VERSION ""

NS_ :

BS_:

BU_: XXX

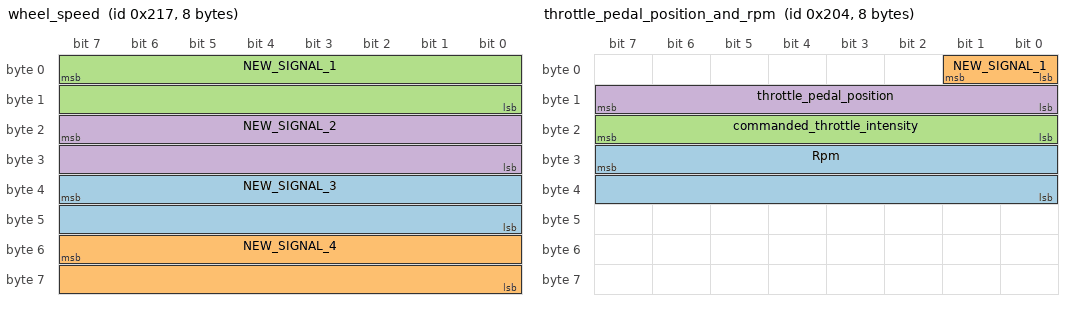
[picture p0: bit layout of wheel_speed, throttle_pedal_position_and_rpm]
BO_ 535 wheel_speed: 8 XXX
 SG_ NEW_SIGNAL_3 : 39|16@0+ (1,0) [0|65535] "" XXX
 SG_ NEW_SIGNAL_4 : 55|16@0+ (1,0) [0|65535] "" XXX
 SG_ NEW_SIGNAL_1 : 7|16@0+ (1,0) [0|65535] "" XXX
 SG_ NEW_SIGNAL_2 : 23|16@0+ (1,0) [0|65535] "" XXX

BO_ 133 steering_angle_2: 8 XXX
 SG_ NEW_SIGNAL_2 : 39|16@0+ (1,0) [0|65535] "" XXX
 SG_ NEW_SIGNAL_1 : 7|16@0+ (1,0) [0|65535] "" XXX

BO_ 516 throttle_pedal_position_and_rpm: 8 XXX
 SG_ Rpm : 31|16@0+ (2.1,0) [0|65535] "rpm" XXX
 SG_ NEW_SIGNAL_1 : 0|2@1+ (1,0) [0|3] "" XXX
 SG_ commanded_throttle_intensity : 23|8@0+ (1,0) [0|255] "" XXX
 SG_ throttle_pedal_position : 15|8@0+ (0,0) [0|255] "" XXX

BO_ 146 steering_related: 8 XXX
 SG_ NEW_SIGNAL_1 : 7|16@0+ (1,0) [0|65535] "" XXX
 SG_ NEW_SIGNAL_2 : 23|16@0+ (1,0) [0|65535] "" XXX

BO_ 145 steering_related: 8 XXX
 SG_ NEW_SIGNAL_1 : 7|16@0+ (1,0) [0|65535] "" XXX
 SG_ NEW_SIGNAL_2 : 23|16@0+ (1,0) [0|65535] "" XXX

BO_ 118 NEW_MSG_3: 8 XXX
 SG_ NEW_SIGNAL_1 : 15|8@0+ (1,0) [0|255] "" XXX

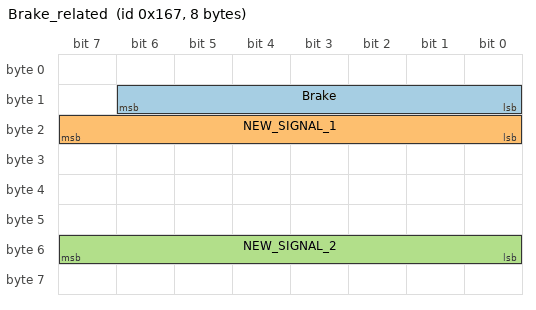
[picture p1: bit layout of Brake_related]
BO_ 359 Brake_related: 8 XXX
 SG_ Brake : 14|7@0+ (1,0) [0|3] "" XXX
 SG_ NEW_SIGNAL_1 : 23|8@0+ (1,0) [0|255] "" XXX
 SG_ NEW_SIGNAL_2 : 55|8@0+ (1,0) [0|255] "" XXX

BO_ 125 brake_pedal: 8 XXX
 SG_ NEW_SIGNAL_1 : 15|8@0+ (0.3,0) [0|100] "percent" XXX

BO_ 534 NEW_MSG_1: 8 XXX
 SG_ NEW_SIGNAL_1 : 23|16@0+ (1,0) [0|65535] "" XXX

BO_ 514 NEW_MSG_2: 8 XXX
 SG_ NEW_SIGNAL_1 : 15|16@0+ (1,0) [0|65535] "" XXX
